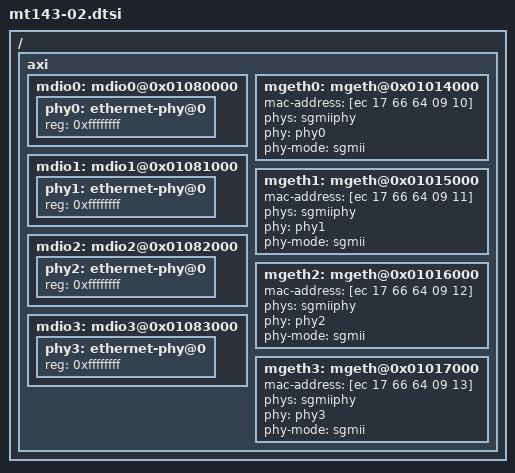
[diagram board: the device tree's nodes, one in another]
/*
 * Device Tree Source for RCM MT43-02 board (Ethernet)
 *
 * This file is licensed under the terms of the GNU General Public
 * License version 2.  This program is licensed "as is" without
 * any warranty of any kind, whether express or implied.
 */

/ {
	axi {
		mdio0: mdio0@0x01080000 {
			status = "okay";
			phy0: ethernet-phy@0 {
				reg = <0xffffffff>; // autodetect
			};
		};

		mgeth0: mgeth@0x01014000 {
			status = "okay";
			mac-address = [ec 17 66 64 09 10];
			phys = <&sgmiiphy>;
			phy = <&phy0>;
			phy-mode = "sgmii";
		};

		mdio1: mdio1@0x01081000 {
			status = "okay";
			phy1: ethernet-phy@0 {
				reg = <0xffffffff>; // autodetect
			};
		};

		mgeth1: mgeth@0x01015000 {
			status = "okay";
			mac-address = [ec 17 66 64 09 11];
			phys = <&sgmiiphy>;
			phy = <&phy1>;
			phy-mode = "sgmii";
		};

		mdio2: mdio2@0x01082000 {
			status = "okay";
			phy2: ethernet-phy@0 {
				reg = <0xffffffff>; // autodetect
			};
		};

		mgeth2: mgeth@0x01016000 {
			status = "okay";
			mac-address = [ec 17 66 64 09 12];
			phys = <&sgmiiphy>;
			phy = <&phy2>;
			phy-mode = "sgmii";
		};

		mdio3: mdio3@0x01083000 {
			status = "okay";
			phy3: ethernet-phy@0 {
				reg = <0xffffffff>; // autodetect
			};
		};

		mgeth3: mgeth@0x01017000 {
			status = "okay";
			mac-address = [ec 17 66 64 09 13];
			phys = <&sgmiiphy>;
			phy = <&phy3>;
			phy-mode = "sgmii";
		};
	};
};
